AUTOSAR XML (schema 00046)
package /ComponentTypes
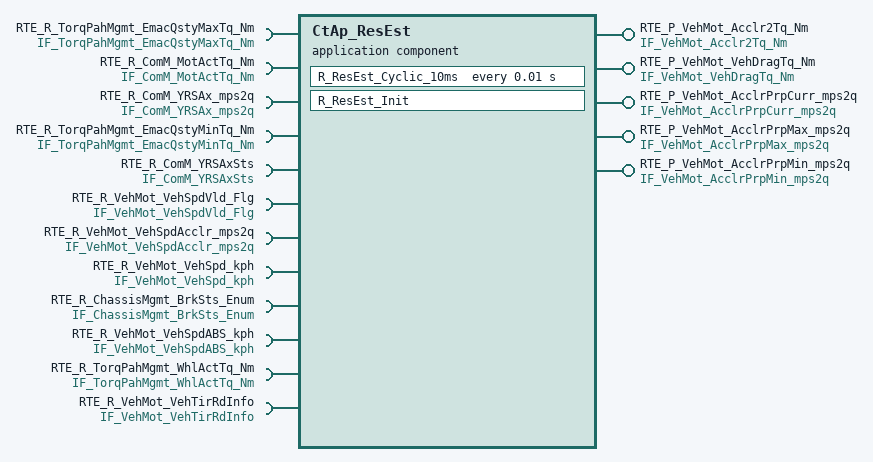
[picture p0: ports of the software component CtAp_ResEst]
  application sw component type CtAp_ResEst
    4 x require port:
      RTE_R_TorqPahMgmt_EmacQstyMaxTq_Nm: nonqueued-receiver-com-spec{data-element=tec_TorqPahMgmt_EmacQstyMaxTq_Nm, filter=data-filter-type=ALWAYS, init-value=0}, required-interface=IF_TorqPahMgmt_EmacQstyMaxTq_Nm
      RTE_R_ComM_MotActTq_Nm: nonqueued-receiver-com-spec{data-element=tec_ComM_MotActTq_Nm, filter=data-filter-type=ALWAYS, init-value=0}, required-interface=IF_ComM_MotActTq_Nm
      RTE_R_ComM_YRSAx_mps2q: nonqueued-receiver-com-spec{data-element=tec_ComM_YRSAx_mps2q, filter=data-filter-type=ALWAYS, init-value=0}, required-interface=IF_ComM_YRSAx_mps2q
      RTE_R_TorqPahMgmt_EmacQstyMinTq_Nm: nonqueued-receiver-com-spec{data-element=tec_TorqPahMgmt_EmacQstyMinTq_Nm, filter=data-filter-type=ALWAYS, init-value=0}, required-interface=IF_TorqPahMgmt_EmacQstyMinTq_Nm
    5 x provide port:
      RTE_P_VehMot_Acclr2Tq_Nm: nonqueued-sender-com-spec{data-element=tec_VehMot_Acclr2Tq_Nm, init-value=0}, provided-interface=IF_VehMot_Acclr2Tq_Nm
      RTE_P_VehMot_VehDragTq_Nm: nonqueued-sender-com-spec{data-element=tec_VehMot_VehDragTq_Nm, init-value=0}, provided-interface=IF_VehMot_VehDragTq_Nm
      RTE_P_VehMot_AcclrPrpCurr_mps2q: nonqueued-sender-com-spec{data-element=tec_VehMot_AcclrPrpCurr_mps2q, init-value=0}, provided-interface=IF_VehMot_AcclrPrpCurr_mps2q
      RTE_P_VehMot_AcclrPrpMax_mps2q: nonqueued-sender-com-spec{data-element=tec_VehMot_AcclrPrpMax_mps2q, init-value=0}, provided-interface=IF_VehMot_AcclrPrpMax_mps2q
      RTE_P_VehMot_AcclrPrpMin_mps2q: nonqueued-sender-com-spec{data-element=tec_VehMot_AcclrPrpMin_mps2q, init-value=0}, provided-interface=IF_VehMot_AcclrPrpMin_mps2q
    8 x require port:
      RTE_R_ComM_YRSAxSts: nonqueued-receiver-com-spec{data-element=tec_ComM_YRSAxSts, filter=data-filter-type=ALWAYS, init-value=0}, required-interface=IF_ComM_YRSAxSts
      RTE_R_VehMot_VehSpdVld_Flg: nonqueued-receiver-com-spec{data-element=tec_VehMot_VehSpdVld_Flg, filter=data-filter-type=ALWAYS, init-value=0}, required-interface=IF_VehMot_VehSpdVld_Flg
      RTE_R_VehMot_VehSpdAcclr_mps2q: nonqueued-receiver-com-spec{data-element=tec_VehMot_VehSpdAcclr_mps2q, filter=data-filter-type=ALWAYS, init-value=0}, required-interface=IF_VehMot_VehSpdAcclr_mps2q
      RTE_R_VehMot_VehSpd_kph: nonqueued-receiver-com-spec{data-element=tec_VehMot_VehSpd_kph, filter=data-filter-type=ALWAYS, init-value=0}, required-interface=IF_VehMot_VehSpd_kph
      RTE_R_ChassisMgmt_BrkSts_Enum: nonqueued-receiver-com-spec{data-element=tec_ChassisMgmt_BrkSts_Enum, filter=data-filter-type=ALWAYS, init-value=0}, required-interface=IF_ChassisMgmt_BrkSts_Enum
      RTE_R_VehMot_VehSpdABS_kph: nonqueued-receiver-com-spec{data-element=tec_VehMot_VehSpdABS_kph, filter=data-filter-type=ALWAYS, init-value=0}, required-interface=IF_VehMot_VehSpdABS_kph
      RTE_R_TorqPahMgmt_WhlActTq_Nm: nonqueued-receiver-com-spec{data-element=tec_TorqPahMgmt_WhlActTq_Nm, filter=data-filter-type=ALWAYS, init-value=0}, required-interface=IF_TorqPahMgmt_WhlActTq_Nm
      RTE_R_VehMot_VehTirRdInfo: nonqueued-receiver-com-spec{data-element=tec_VehMot_VehTirRdInfo, filter=data-filter-type=ALWAYS, init-value=0}, required-interface=IF_VehMot_VehTirRdInfo
    behavior CtAp_ResEst_InternalBehavior
      timing event TMT_R_ResEst_Cyclic_10ms: start-on-event=R_ResEst_Cyclic_10ms, period=0.01
      init event CtAp_ResEst_InitEvent: start-on-event=R_ResEst_Init
      runnable R_ResEst_Cyclic_10ms
        data-receive-point-by-arguments:
          12 x access:
            REC_RTE_R_ComM_MotActTq_Nm_tec_ComM_MotActTq_Nm: accessed-variable=RTE_R_ComM_MotActTq_Nm.tec_ComM_MotActTq_Nm
            REC_RTE_R_ComM_YRSAxSts_Flg_tec_ComM_YRSAxSts_Flg: accessed-variable=RTE_R_ComM_YRSAxSts.tec_ComM_YRSAxSts
            REC_RTE_R_ComM_YRSAx_mps2q_tec_ComM_YRSAx_mps2q: accessed-variable=RTE_R_ComM_YRSAx_mps2q.tec_ComM_YRSAx_mps2q
            REC_RTE_R_TorqPahMgmt_EmacQstyMaxTq_Nm_tec_TorqPahMgmt_EmacQstyMaxTq_Nm: accessed-variable=RTE_R_TorqPahMgmt_EmacQstyMaxTq_Nm.tec_TorqPahMgmt_EmacQstyMaxTq_Nm
            REC_RTE_R_TorqPahMgmt_EmacQstyMinTq_Nm_tec_TorqPahMgmt_EmacQstyMinTq_Nm: accessed-variable=RTE_R_TorqPahMgmt_EmacQstyMinTq_Nm.tec_TorqPahMgmt_EmacQstyMinTq_Nm
            REC_RTE_R_VehMot_VehSpdAcclr_mps2q_tec_VehMot_VehSpdAcclr_mps2q: accessed-variable=RTE_R_VehMot_VehSpdAcclr_mps2q.tec_VehMot_VehSpdAcclr_mps2q
            REC_RTE_R_VehMot_VehSpdVld_Flg_tec_VehMot_VehSpdVld_Flg: accessed-variable=RTE_R_VehMot_VehSpdVld_Flg.tec_VehMot_VehSpdVld_Flg
            REC_RTE_R_VehMot_VehSpd_kph_tec_VehMot_VehSpd_kph: accessed-variable=RTE_R_VehMot_VehSpd_kph.tec_VehMot_VehSpd_kph
            REC_RTE_R_ChassisMgmt_BrkSts_Enum_tec_ChassisMgmt_BrkSts_Enum: accessed-variable=RTE_R_ChassisMgmt_BrkSts_Enum.tec_ChassisMgmt_BrkSts_Enum
            REC_RTE_R_TorqPahMgmt_WhlActTq_Nm_tec_TorqPahMgmt_WhlActTq_Nm: accessed-variable=RTE_R_TorqPahMgmt_WhlActTq_Nm.tec_TorqPahMgmt_WhlActTq_Nm
            REC_RTE_R_VehMot_VehSpdABS_kph_tec_VehMot_VehSpdABS_kph: accessed-variable=RTE_R_VehMot_VehSpdABS_kph.tec_VehMot_VehSpdABS_kph
            REC_RTE_R_VehMot_VehTirRdInfo_tec_VehMot_VehTirRdInfo: accessed-variable=RTE_R_VehMot_VehTirRdInfo.tec_VehMot_VehTirRdInfo
        data-send-points:
          5 x access:
            SEND_RTE_P_VehMot_Acclr2Tq_Nm_tec_VehMot_Acclr2Tq_Nm: accessed-variable=RTE_P_VehMot_Acclr2Tq_Nm.tec_VehMot_Acclr2Tq_Nm
            SEND_RTE_P_VehMot_AcclrPrpCurr_mps2q_tec_VehMot_AcclrPrpCurr_mps2q: accessed-variable=RTE_P_VehMot_AcclrPrpCurr_mps2q.tec_VehMot_AcclrPrpCurr_mps2q
            SEND_RTE_P_VehMot_AcclrPrpMax_mps2q_tec_VehMot_AcclrPrpMax_mps2q: accessed-variable=RTE_P_VehMot_AcclrPrpMax_mps2q.tec_VehMot_AcclrPrpMax_mps2q
            SEND_RTE_P_VehMot_AcclrPrpMin_mps2q_tec_VehMot_AcclrPrpMin_mps2q: accessed-variable=RTE_P_VehMot_AcclrPrpMin_mps2q.tec_VehMot_AcclrPrpMin_mps2q
            SEND_RTE_P_VehMot_VehDragTq_Nm_tec_VehMot_VehDragTq_Nm: accessed-variable=RTE_P_VehMot_VehDragTq_Nm.tec_VehMot_VehDragTq_Nm
      runnable R_ResEst_Init
  swc implementation CtAp_ResEst_Implementation: behavior=CtAp_ResEst_InternalBehavior
